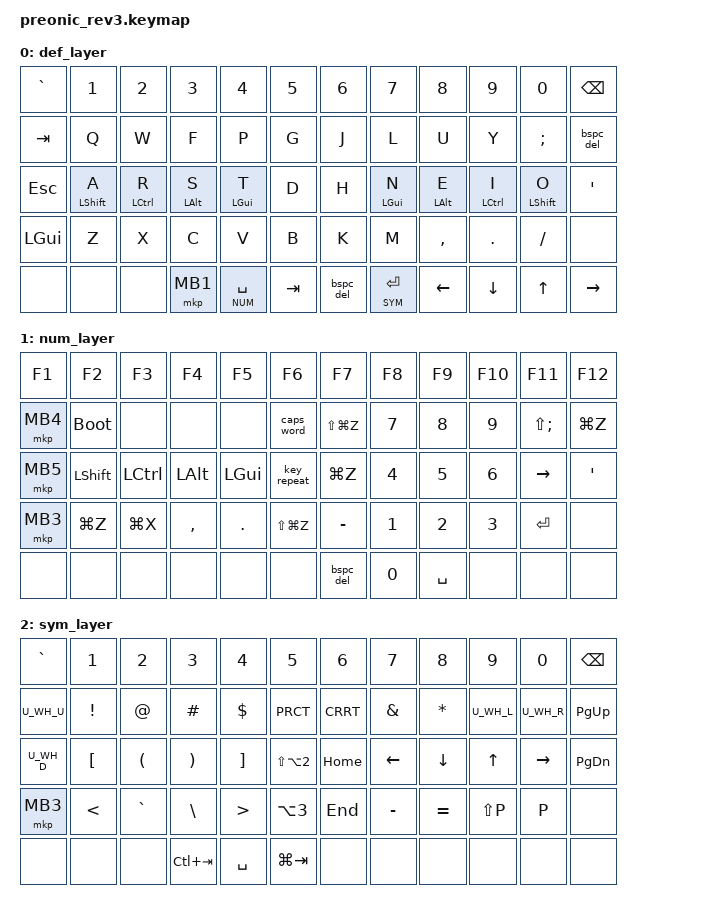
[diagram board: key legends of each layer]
#include <behaviors.dtsi>
#include <dt-bindings/zmk/keys.h>
#include <dt-bindings/zmk/bt.h>
#include <dt-bindings/zmk/mouse.h>

#include "../zmk-nodefree-config/keypos_def/keypos_42keys.h"
#include "../zmk-nodefree-config/helper.h"

#define DEF 0
#define NUM 1
#define SYM 2

#include <behaviors.dtsi>
#include <dt-bindings/zmk/keys.h>
#include <dt-bindings/zmk/bt.h>
#include <dt-bindings/zmk/mouse.h>

#define U_RDO &kp LS(LG(Z))
#define U_PST &kp LG(V)
#define U_CPY &kp LG(C)
#define U_CUT &kp LG(X)
#define U_UND &kp LG(Z)

// #include "combos.dtsi"  // must be sourced after layer-shortcuts
#include "mouse.dtsi"

// Behavior Overrides
&lt {
    tapping-term-ms = <200>;
    flavor = "tap-preferred";
    tapping-term-ms = <200>;
    quick-tap-ms = <150>;
    global-quick-tap;
};

// Sticky key
&sk {
    // release-after-ms = <2000>;
    quick-release;
};

// Sticky layer
&sl {
    release-after-ms = <2000>;
};

// KEY POSITION REFERENCE
// ------------------------------------------------------------------------
// | 00 | 01 | 02 | 03 | 04 | 05 |          | 06 | 07 | 08 | 09 | 10 | 11 |
// | 12 | 13 | 14 | 15 | 16 | 17 |          | 18 | 19 | 20 | 21 | 22 | 23 |
// | 24 | 25 | 26 | 27 | 28 | 29 |          | 30 | 31 | 32 | 33 | 34 | 35 |
// | 36 | 37 | 38 | 39 | 40 | 41 |          | 42 | 43 | 44 | 45 | 46 | 47 |
// | 48 | 49 | 50 | 51 | 52 | 53 |          | 54 | 55 | 56 | 57 | 58 | 59 |


/ {
    macros {
        spotlight: spotlight {
            label = "spotlight";
            compatible = "zmk,behavior-macro";
            #binding-cells = <0>;
            bindings = <&macro_press &kp LGUI>, <&macro_tap &kp SPACE>, <&macro_release &kp LGUI>;
        };

        // Emoji
        mac_emoji: mac_emoji {
            label = "mac_emoji";
            compatible = "zmk,behavior-macro";
            #binding-cells = <0>;
            bindings = <&macro_press &kp LGUI>, <&macro_press &kp LCTRL>, <&macro_tap &kp SPACE>, <&macro_release &kp LCTRL>, <&macro_release &kp LGUI>;
        };

        ij: ij {
            label = "ij";
            compatible = "zmk,behavior-macro";
            //wait-ms = <30>;
            //tap-ms = <30>;
            #binding-cells = <0>;
            // ij (=LY in qwerty)
            bindings = <&macro_tap &kp I &kp J>;
        };

        sch: sch {
            label = "sch";
            compatible = "zmk,behavior-macro";
            //wait-ms = <30>;
            //tap-ms = <30>;
            #binding-cells = <0>;
            // sch (=DCH in qwerty)
            bindings = <&macro_tap &kp S &kp C &kp H>;
        };

        // control + num
        cnum: cnum {
            label = "cnum";
            compatible = "zmk,behavior-macro";
            wait-ms = <0>;
            tap-ms = <30>;
            #binding-cells = <0>;
            bindings
                = <&macro_press &mo 1 &kp LCTRL>
                , <&macro_pause_for_release>
                , <&macro_release &mo 1 &kp LCTRL>;
        };

        // option + num
        anum: anum {
            label = "anum";
            compatible = "zmk,behavior-macro";
            wait-ms = <0>;
            tap-ms = <30>;
            #binding-cells = <0>;
            bindings
                = <&macro_press &mo 1 &kp LALT>
                , <&macro_pause_for_release>
                , <&macro_release &mo 1 &kp LALT>;
        };

        // gui + num
        gnum: gnum {
            label = "gnum";
            compatible = "zmk,behavior-macro";
            wait-ms = <0>;
            tap-ms = <30>;
            #binding-cells = <0>;
            bindings
                = <&macro_press &mo 1 &kp LGUI>
                , <&macro_pause_for_release>
                , <&macro_release &mo 1 &kp LGUI>;
        };

    };

#define CNUM &cnum
#define ANUM &anum
#define GNUM &gnum

// KEY POSITION REFERENCE
// ------------------------------------------------------------------------
// | 00 | 01 | 02 | 03 | 04 | 05 |          | 06 | 07 | 08 | 09 | 10 | 11 |
// | 12 | 13 | 14 | 15 | 16 | 17 |          | 18 | 19 | 20 | 21 | 22 | 23 |
// | 24 | 25 | 26 | 27 | 28 | 29 |          | 30 | 31 | 32 | 33 | 34 | 35 |
// | 36 | 37 | 38 | 39 | 40 | 41 |          | 42 | 43 | 44 | 45 | 46 | 47 |
// | 48 | 49 | 50 | 51 | 52 | 53 |          | 54 | 55 | 56 | 57 | 58 | 59 |


    combos {
        compatible = "zmk,combos";

        combo_tab {
          timeout-ms = <20>;
          key-positions = <12 13>;
          bindings = <&kp TAB>;
        };

        COMBO_SCH {
          timeout-ms = <20>;
          key-positions = <15 16>;
          bindings = <&sch>;
        };

        combo_ij {
          timeout-ms = <20>;
          key-positions = <20 21>;
          bindings = <&ij>;
        };

        //  combo_enter {
        //    timeout-ms = <20>;
          //  key-positions = <13 14>;
          //  bindings = <&kp ENTER>;
        //};
    };

    behaviors {

        bspc_del: backspace_delete {
            compatible = "zmk,behavior-mod-morph";
            label = "BACKSPACE_DELETE";
            #binding-cells = <0>;
            bindings = <&kp BACKSPACE>, <&kp DELETE>;
            mods = <(MOD_LCTL)>;
            // keep-mods = <(MOD_RSFT)>;
        };


        td_multi_mac: tap_dance_multi_mac {
            compatible = "zmk,behavior-tap-dance";
            label = "TAP_DANCE_MULTI_MAC";
            #binding-cells = <0>;
            tapping-term-ms = <200>;
            bindings = <&kp ESC>, <&spotlight>, <&mac_emoji>;
        };

        bm: bottom_row_mods {
            compatible = "zmk,behavior-hold-tap";
            label = "BOTTOM_ROW_MODS";
            #binding-cells = <2>;
            tapping-term-ms = <135>;
            quick-tap-ms = <0>;
            flavor = "tap-preferred";
            bindings = <&kp>, <&kp>;
        };

        cm: code_row_mods {
            compatible = "zmk,behavior-hold-tap";
            label = "CODE_ROW_MODS";
            #binding-cells = <2>;
            tapping-term-ms = <200>;
            quick-tap-ms = <0>;
            flavor = "tap-preferred";
            bindings = <&kp>, <&kp>;
            retro-tap;
        };

        sm: space_mod {
            compatible = "zmk,behavior-hold-tap";
            label = "SPACE_MOD";
            #binding-cells = <2>;
            flavor = "balanced";
            tapping-term-ms = <200>;
            quick-tap-ms = <125>;
            bindings = <&kp>, <&kp>;
        };

        gmt: global-quick-mod-tap {
            compatible = "zmk,behavior-hold-tap";
            label = "gmt";
            #binding-cells = <2>;
            flavor = "tap-preferred";
            tapping-term-ms = <220>;
            quick-tap-ms = <150>;
            global-quick-tap;
            bindings = <&kp>, <&kp>;
        };

        glt: global-quick-layer-tap {
            compatible = "zmk,behavior-hold-tap";
            label = "glt";
            #binding-cells = <2>;
            flavor = "tap-preferred";
            tapping-term-ms = <200>;
            quick-tap-ms = <150>;
            global-quick-tap;
            bindings = <&mo>, <&kp>;
        };

        gbt: global-quick-mousebutton-tap {
            compatible = "zmk,behavior-hold-tap";
            label = "gbt";
            #binding-cells = <2>;
            flavor = "tap-preferred";
            tapping-term-ms = <200>;
            quick-tap-ms = <150>;
            global-quick-tap;
            bindings = <&mkp>, <&kp>;
        };

        gkm: global-mod-mouse-tap {
            compatible = "zmk,behavior-hold-tap";
            label = "gkm";
            #binding-cells = <2>;
            flavor = "tap-preferred";
            tapping-term-ms = <200>;
            quick-tap-ms = <150>;
            global-quick-tap;
            bindings = <&kp>, <&mkp>;
        };


};


    chosen { zmk,matrix_transform = &layout_grid_transform; };
    keymap {
        compatible = "zmk,keymap";
        def_layer {
            // KEY POSITION REFERENCE
            // ------------------------------------------------------------------------
            // | 00 | 01 | 02 | 03 | 04 | 05 |          | 06 | 07 | 08 | 09 | 10 | 11 |
            // | 12 | 13 | 14 | 15 | 16 | 17 |          | 18 | 19 | 20 | 21 | 22 | 23 |
            // | 24 | 25 | 26 | 27 | 28 | 29 |          | 30 | 31 | 32 | 33 | 34 | 35 |
            // | 36 | 37 | 38 | 39 | 40 | 41 |          | 42 | 43 | 44 | 45 | 46 | 47 |
            // | 48 | 49 | 50 | 51 | 52 | 53 |          | 54 | 55 | 56 | 57 | 58 | 59 |

            //  -------------------------------------------------------------------------------------------------
            // |  GRAV |  1   |  2   |  3   |  4    |  5     |   6     |  7     |  8   |  9    |   0   | BSPC   |
            // |  TAB  |  Q   |  W   |  E   |  R    |  T     |   Y     |  U     |  I   |  O    |   P   |BSPC/DEL|
            // |  ESC  |  A   |  S   |  D   |  F    |  G     |   H     |  J     |  K   |  L    |   ;   |  '     |
            // | SHIFT |  Z   |  X   |  C   |  V    |  B     |   N     |  M     |  ,   |  .    |   /   | ---    |
            // |       | LGUI | LALT | LCTL | NUM   | SPACE  |  SPACE  |  SYM   | LEFT |  DOWN |   UP  | RIGHT  |
            bindings = <
                &kp GRAVE   &kp N1     &kp N2    &kp N3    &kp N4     &kp N5            &kp N6     &kp N7        &kp N8     &kp N9    &kp N0     &kp BSPC
                 &kp TAB     &kp Q          &kp W          &kp F           &kp P           &kp G                   &kp J         &kp L          &kp U           &kp Y          &kp SEMI          &bspc_del
                 &kp ESC     &gmt LSHFT A   &gmt LCTRL R   &gmt LALT S     &gmt LGUI T     &kp D                   &kp H         &gmt LGUI N    &gmt LALT E     &gmt LCTRL I   &gmt LSHFT O      &kp SQT
                 &kp LGUI    &kp Z          &kp X          &kp C           &kp V           &kp B                   &kp K         &kp M          &kp COMMA       &kp DOT        &kp SLASH         &none
                 &none       &none          &none          &mkp MB1        &glt NUM SPACE  &kp TAB                 &bspc_del     &glt SYM RET   &kp LEFT        &kp DOWN       &kp UP            &kp RIGHT
                >;
        };
        num_layer {
            // -------------------------------------------------------------------------------------------
            // |   `   |  1   |  2   |  3   |  4   |   5   |   6   |   7   |   8  |  9   |   0   | BSPC  |
            // |   `   |  1   |  2   |  3   |  4   |   5   |   6   |   7   |   8  |  9   |   0   | DEL   |
            // |  DEL  |  F1  |  F2  |  F3  |  F4  |  F5   |  F6   |   -   |   =  |  [   |   ]   |  \    |
            // |       |  F7  |  F8  |  F9  |  F10 |  F11  |  F12  |   #   |   \  | PGUP |  PGDN |       |
            // |       |      |      |      |      | SHIFT |       |       | NEXT | VOL- |  VOL+ | PLAY  |
            bindings = <
                &kp F1      &kp F2         &kp F3          &kp F4          &kp F5        &kp F6                   &kp F7        &kp F8         &kp F9          &kp F10        &kp F11           &kp F12
                &mkp MB4    &bootloader    &none           &none           &none         &caps_word               U_RDO         &kp NUM_7      &kp NUM_8       &kp NUM_9      &kp LS(SEMI)      U_UND
                &mkp MB5    &kp LSHFT      &kp LCTRL       &kp LALT        &kp LGUI      &key_repeat              U_UND       &kp NUM_4      &kp NUM_5       &kp NUM_6      &kp RIGHT         &kp SQT
                &mkp MB3    U_UND          U_CUT           &kp COMMA       &kp DOT       U_RDO                    &kp MINUS     &kp NUM_1      &kp NUM_2       &kp NUM_3      &kp RET           &none
                &none       &none          &none           &none           &none         &none                    &bspc_del     &kp NUM_0      &kp SPACE       &none          &none             &none
                >;
        };

        sym_layer {
            // -------------------------------------------------------------------------------------------
            // |   `   |  1   |  2   |  3   |  4   |   5   |   6   |   7   |   8  |  9   |   0   | BSPC  |
            // |   `   |  1   |  2   |  3   |  4   |   5   |   6   |   7   |   8  |  9   |   0   | DEL   |
            // |  DEL  |  F1  |  F2  |  F3  |  F4  |  F5   |  F6   |   -   |   =  |  [   |   ]   |  \    |
            // |       |  F7  |  F8  |  F9  |  F10 |  F11  |  F12  |   #   |   \  | PGUP |  PGDN |       |
            // |       |      |      |      |      | SHIFT |       |       | NEXT | VOL- |  VOL+ | PLAY  |
            bindings = <
                &kp GRAVE   &kp N1         &kp N2          &kp N3          &kp N4        &kp N5                   &kp N6        &kp N7          &kp N8         &kp N9         &kp N0             &kp BSPC
                U_WH_U      &kp EXCL       &kp AT          &kp HASH        &kp DLLR      &kp PRCT                 &kp CRRT      &kp AMPS        &kp ASTRK      U_WH_L         U_WH_R             &kp PG_UP
                U_WH_D      &kp LBKT       &kp LPAR        &kp RPAR        &kp RBKT      &kp LS(LA(NUM_2))        &kp HOME      &kp LEFT        &kp DOWN       &kp UP         &kp RIGHT          &kp PG_DN
                &mkp MB3    &kp LT         &kp GRAVE       &kp BSLH        &kp GT        &kp LA(NUM_3)            &kp END       &kp MINUS       &kp EQL        &kp LS(P)      &kp P              &none
                &none       &none          &none           &kp LC(TAB)     &kp SPACE     &kp LG(TAB)              &none         &none           &none          &none          &none              &none
                >;
        };
    };
};
